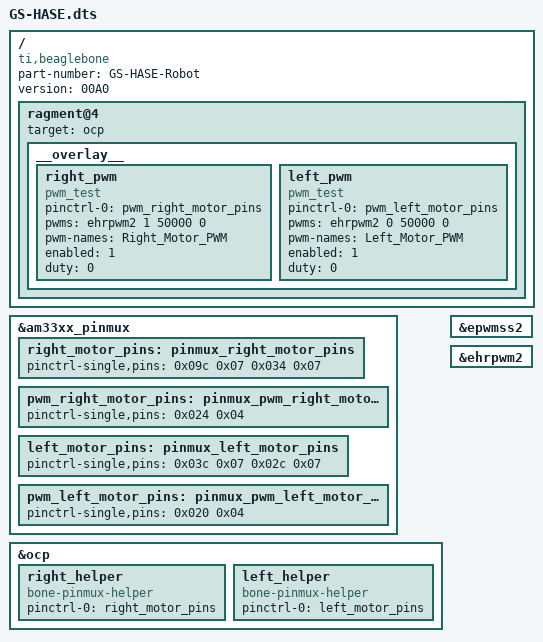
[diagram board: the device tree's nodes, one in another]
/*
* Copyright (C) 2012 Texas Instruments Incorporated - http://www.ti.com/
*
* This program is free software; you can redistribute it and/or modify
* it under the terms of the GNU General Purpose License Version 2 as
* published by the Free Software Foundation
*
* Original from: github.com/jadonk/validation-scripts/blob/master/test-capemgr/ 
*
* Modified by Gary Servin to work with a BeagleBone Black Controlled Robot
* called Hase
*/

/dts-v1/;
/plugin/;

/{
    compatible = "ti,beaglebone", "ti,beaglebone-black";
    part-number = "GS-HASE-Robot";
    version = "00A0";

    fragment@0 {
        target = <&am33xx_pinmux>;

        __overlay__ {
            right_motor_pins: pinmux_right_motor_pins {
                pinctrl-single,pins = <
                    0x09c 0x07  /* P8_9  69 OUTPUT MODE7 - Right Motor Reverse */
                    0x034 0x07  /* P8_11 45 OUTPUT MODE7 - Right Motor Forward */

                    /* OUTPUT  GPIO(mode7) 0x07 pulldown, 0x17 pullup, 0x?f no pullup/down */
                    /* INPUT   GPIO(mode7) 0x27 pulldown, 0x37 pullup, 0x?f no pullup/down */
                >;
            };

            pwm_right_motor_pins: pinmux_pwm_right_motor_pins {
                pinctrl-single,pins = <
                    0x024 0x04  /* P8_13 23 OUTPUT MODE7 - Right Motor PWM */
                >;
            };

            left_motor_pins: pinmux_left_motor_pins {
                pinctrl-single,pins = <
                    0x03c 0x07  /* P8_15 47 OUTPUT MODE7 - Left Motor Reverse */
                    0x02c 0x07  /* P8_17 27 OUTPUT MODE7 - Left Motor Forward */

                    /* OUTPUT  GPIO(mode7) 0x07 pulldown, 0x17 pullup, 0x?f no pullup/down */
                    /* INPUT   GPIO(mode7) 0x27 pulldown, 0x37 pullup, 0x?f no pullup/down */
                >;
            };

            pwm_left_motor_pins: pinmux_pwm_left_motor_pins {
                pinctrl-single,pins = <
                    0x020 0x04  /* P8_19 22 OUTPUT MODE7 - Left Motor PWM */
                >;
            };

        };
    };

    fragment@1 {
        target = <&ocp>;
        __overlay__ {
            right_helper: right_helper {
                compatible = "bone-pinmux-helper";
                pinctrl-names = "default";
                pinctrl-0 = <&right_motor_pins>;
                status = "okay";
            };

            left_helper: left_helper {
                compatible = "bone-pinmux-helper";
                pinctrl-names = "default";
                pinctrl-0 = <&left_motor_pins>;
                status = "okay";
            };
        };
    };

    fragment@2 {
        target = <&epwmss2>;
        __overlay__ {
            status = "okay";
        };
    };

    fragment@3 {
        target = <&ehrpwm2>;
        __overlay__ {
            status = "okay";
        };
    };

    ragment@4 {
        target = <&ocp>;
        __overlay__ {
            right_pwm {
                compatible      = "pwm_test";
                pinctrl-names   = "default";
                pinctrl-0       = <&pwm_right_motor_pins>;
                pwms            = <&ehrpwm2 1 50000 0>;
                pwm-names       = "Right_Motor_PWM";
                enabled         = <1>;
                duty            = <0>;
                status          = "okay";
            };
            left_pwm {
                compatible      = "pwm_test";
                pinctrl-names   = "default";
                pinctrl-0       = <&pwm_left_motor_pins>;
                pwms            = <&ehrpwm2 0 50000 0>;
                pwm-names       = "Left_Motor_PWM";
                enabled         = <1>;
                duty            = <0>;
                status          = "okay";
            };
        };
    };
};
